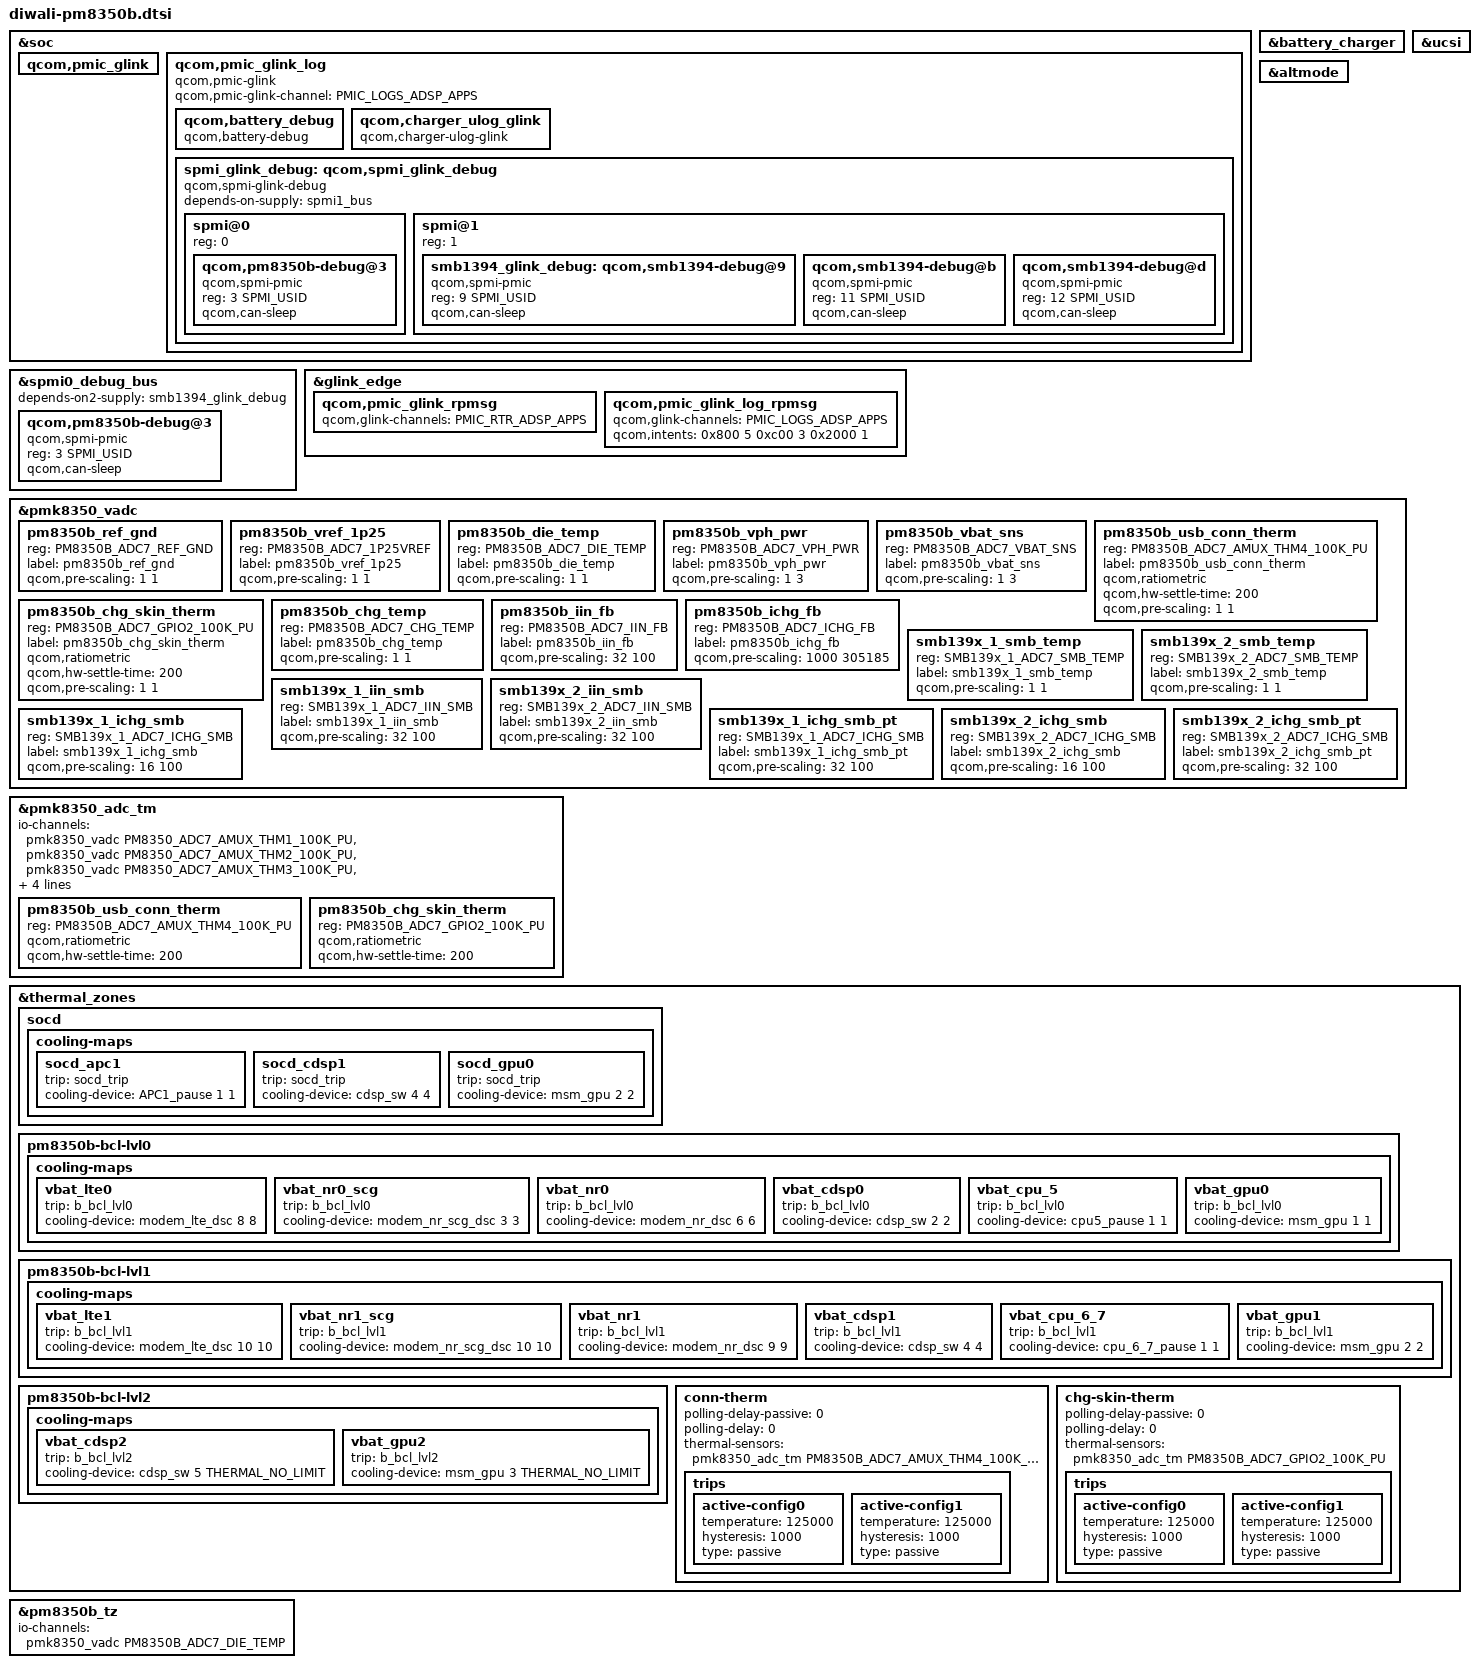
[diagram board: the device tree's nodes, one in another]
#include <dt-bindings/clock/qcom,rpmh.h>
#include <dt-bindings/thermal/thermal_qti.h>
#include <dt-bindings/iio/qcom,spmi-adc7-pm8350b.h>
#include <dt-bindings/iio/qcom,spmi-adc7-smb139x.h>
#include "pm8350b.dtsi"

&soc {
	qcom,pmic_glink {
		status = "okay";
	};

	qcom,pmic_glink_log {
		compatible = "qcom,pmic-glink";
		qcom,pmic-glink-channel = "PMIC_LOGS_ADSP_APPS";

		qcom,battery_debug {
			compatible = "qcom,battery-debug";
		};

		qcom,charger_ulog_glink {
			compatible = "qcom,charger-ulog-glink";
		};

		spmi_glink_debug: qcom,spmi_glink_debug {
			compatible = "qcom,spmi-glink-debug";
			#address-cells = <1>;
			#size-cells = <0>;
			depends-on-supply = <&spmi1_bus>;

			/* Primary SPMI bus */
			spmi@0 {
				reg = <0>;
				#address-cells = <2>;
				#size-cells = <0>;

				qcom,pm8350b-debug@3 {
					compatible = "qcom,spmi-pmic";
					reg = <3 SPMI_USID>;
					qcom,can-sleep;
				};
			};

			/* Secondary SPMI bus */
			spmi@1 {
				reg = <1>;
				#address-cells = <2>;
				#size-cells = <0>;

				smb1394_glink_debug: qcom,smb1394-debug@9 {
					compatible = "qcom,spmi-pmic";
					reg = <9 SPMI_USID>;
					qcom,can-sleep;
				};

				qcom,smb1394-debug@b {
					compatible = "qcom,spmi-pmic";
					reg = <11 SPMI_USID>;
					qcom,can-sleep;
				};

				qcom,smb1394-debug@d {
					compatible = "qcom,spmi-pmic";
					reg = <12 SPMI_USID>;
					qcom,can-sleep;
				};
			};
		};
	};
};

&spmi0_debug_bus {
	depends-on2-supply = <&smb1394_glink_debug>;
	qcom,pm8350b-debug@3 {
		compatible = "qcom,spmi-pmic";
		reg = <3 SPMI_USID>;
		#address-cells = <2>;
		#size-cells = <0>;
		qcom,can-sleep;
	};
};

&glink_edge {
	qcom,pmic_glink_rpmsg {
		qcom,glink-channels = "PMIC_RTR_ADSP_APPS";
	};

	qcom,pmic_glink_log_rpmsg {
		qcom,glink-channels = "PMIC_LOGS_ADSP_APPS";
		qcom,intents = <0x800  5
			0xc00 3
			0x2000 1>;
	};
};

&battery_charger {
	status = "okay";
};

&ucsi {
	status = "okay";
};

&altmode {
	status = "okay";
};

&pmk8350_vadc {
	pm8350b_ref_gnd {
		reg = <PM8350B_ADC7_REF_GND>;
		label = "pm8350b_ref_gnd";
		qcom,pre-scaling = <1 1>;
	};

	pm8350b_vref_1p25 {
		reg = <PM8350B_ADC7_1P25VREF>;
		label = "pm8350b_vref_1p25";
		qcom,pre-scaling = <1 1>;
	};

	pm8350b_die_temp {
		reg = <PM8350B_ADC7_DIE_TEMP>;
		label = "pm8350b_die_temp";
		qcom,pre-scaling = <1 1>;
	};

	pm8350b_vph_pwr {
		reg = <PM8350B_ADC7_VPH_PWR>;
		label = "pm8350b_vph_pwr";
		qcom,pre-scaling = <1 3>;
	};

	pm8350b_vbat_sns {
		reg = <PM8350B_ADC7_VBAT_SNS>;
		label = "pm8350b_vbat_sns";
		qcom,pre-scaling = <1 3>;
	};

	pm8350b_usb_conn_therm {
		reg = <PM8350B_ADC7_AMUX_THM4_100K_PU>;
		label = "pm8350b_usb_conn_therm";
		qcom,ratiometric;
		qcom,hw-settle-time = <200>;
		qcom,pre-scaling = <1 1>;
	};

	pm8350b_chg_skin_therm {
		reg = <PM8350B_ADC7_GPIO2_100K_PU>;
		label = "pm8350b_chg_skin_therm";
		qcom,ratiometric;
		qcom,hw-settle-time = <200>;
		qcom,pre-scaling = <1 1>;
	};

	pm8350b_chg_temp {
		reg = <PM8350B_ADC7_CHG_TEMP>;
		label = "pm8350b_chg_temp";
		qcom,pre-scaling = <1 1>;
	};

	pm8350b_iin_fb {
		reg = <PM8350B_ADC7_IIN_FB>;
		label = "pm8350b_iin_fb";
		qcom,pre-scaling = <32 100>;
	};

	pm8350b_ichg_fb {
		reg = <PM8350B_ADC7_ICHG_FB>;
		label = "pm8350b_ichg_fb";
		qcom,pre-scaling = <1000 305185>;
	};

	smb139x_1_smb_temp {
		reg = <SMB139x_1_ADC7_SMB_TEMP>;
		label = "smb139x_1_smb_temp";
		qcom,pre-scaling = <1 1>;
	};

	smb139x_2_smb_temp {
		reg = <SMB139x_2_ADC7_SMB_TEMP>;
		label = "smb139x_2_smb_temp";
		qcom,pre-scaling = <1 1>;
	};

	smb139x_1_iin_smb {
		reg = <SMB139x_1_ADC7_IIN_SMB>;
		label = "smb139x_1_iin_smb";
		qcom,pre-scaling = <32 100>;
	};

	smb139x_2_iin_smb {
		reg = <SMB139x_2_ADC7_IIN_SMB>;
		label = "smb139x_2_iin_smb";
		qcom,pre-scaling = <32 100>;
	};

	smb139x_1_ichg_smb {
		reg = <SMB139x_1_ADC7_ICHG_SMB>;
		label = "smb139x_1_ichg_smb";
		qcom,pre-scaling = <16 100>;
	};

	smb139x_1_ichg_smb_pt {
		reg = <SMB139x_1_ADC7_ICHG_SMB>;
		label = "smb139x_1_ichg_smb_pt";
		qcom,pre-scaling = <32 100>;
	};

	smb139x_2_ichg_smb {
		reg = <SMB139x_2_ADC7_ICHG_SMB>;
		label = "smb139x_2_ichg_smb";
		qcom,pre-scaling = <16 100>;
	};

	smb139x_2_ichg_smb_pt {
		reg = <SMB139x_2_ADC7_ICHG_SMB>;
		label = "smb139x_2_ichg_smb_pt";
		qcom,pre-scaling = <32 100>;
	};
};

&pmk8350_adc_tm {
	io-channels = <&pmk8350_vadc PM8350_ADC7_AMUX_THM1_100K_PU>,
			<&pmk8350_vadc PM8350_ADC7_AMUX_THM2_100K_PU>,
			<&pmk8350_vadc PM8350_ADC7_AMUX_THM3_100K_PU>,
			<&pmk8350_vadc PM8350_ADC7_AMUX_THM4_100K_PU>,
			<&pmk8350_vadc PMK8350_ADC7_AMUX_THM1_100K_PU>,
			<&pmk8350_vadc PM8350B_ADC7_AMUX_THM4_100K_PU>,
			<&pmk8350_vadc PM8350B_ADC7_GPIO2_100K_PU>;

	pm8350b_usb_conn_therm {
		reg = <PM8350B_ADC7_AMUX_THM4_100K_PU>;
		qcom,ratiometric;
		qcom,hw-settle-time = <200>;
	};

	pm8350b_chg_skin_therm {
		reg = <PM8350B_ADC7_GPIO2_100K_PU>;
		qcom,ratiometric;
		qcom,hw-settle-time = <200>;
	};
};

&thermal_zones {
	socd {
		cooling-maps {
			socd_apc1 {
				trip = <&socd_trip>;
				cooling-device = <&APC1_pause 1 1>;
			};

			socd_cdsp1 {
				trip = <&socd_trip>;
				cooling-device = <&cdsp_sw 4 4>;
			};

			socd_gpu0 {
				trip = <&socd_trip>;
				cooling-device = <&msm_gpu 2 2>;
			};
		};
	};


	pm8350b-bcl-lvl0 {
		cooling-maps {
			vbat_lte0 {
				trip = <&b_bcl_lvl0>;
				cooling-device = <&modem_lte_dsc 8 8>;
			};

			vbat_nr0_scg {
				trip = <&b_bcl_lvl0>;
				cooling-device = <&modem_nr_scg_dsc 3 3>;
			};

			vbat_nr0 {
				trip = <&b_bcl_lvl0>;
				cooling-device = <&modem_nr_dsc 6 6>;
			};

			vbat_cdsp0 {
				trip = <&b_bcl_lvl0>;
				cooling-device = <&cdsp_sw 2 2>;
			};

			vbat_cpu_5 {
				trip = <&b_bcl_lvl0>;
				cooling-device = <&cpu5_pause 1 1>;
			};

			vbat_gpu0 {
				trip = <&b_bcl_lvl0>;
				cooling-device = <&msm_gpu 1 1>;
			};
		};
	};

	pm8350b-bcl-lvl1 {
		cooling-maps {
			vbat_lte1 {
				trip = <&b_bcl_lvl1>;
				cooling-device = <&modem_lte_dsc 10 10>;
			};

			vbat_nr1_scg {
				trip = <&b_bcl_lvl1>;
				cooling-device = <&modem_nr_scg_dsc 10 10>;
			};

			vbat_nr1 {
				trip = <&b_bcl_lvl1>;
				cooling-device = <&modem_nr_dsc 9 9>;
			};

			vbat_cdsp1 {
				trip = <&b_bcl_lvl1>;
				cooling-device = <&cdsp_sw 4 4>;
			};

			vbat_cpu_6_7 {
				trip = <&b_bcl_lvl1>;
				cooling-device = <&cpu_6_7_pause 1 1>;
			};

			vbat_gpu1 {
				trip = <&b_bcl_lvl1>;
				cooling-device = <&msm_gpu 2 2>;
			};
		};
	};

	pm8350b-bcl-lvl2 {
		cooling-maps {
			vbat_cdsp2 {
				trip = <&b_bcl_lvl2>;
				cooling-device = <&cdsp_sw 5 THERMAL_NO_LIMIT>;
			};

			vbat_gpu2 {
				trip = <&b_bcl_lvl2>;
				cooling-device = <&msm_gpu 3 THERMAL_NO_LIMIT>;
			};
		};
	};

	conn-therm {
		polling-delay-passive = <0>;
		polling-delay = <0>;
		thermal-sensors =  <&pmk8350_adc_tm PM8350B_ADC7_AMUX_THM4_100K_PU>;
		trips {
			active-config0 {
				temperature = <125000>;
				hysteresis = <1000>;
				type = "passive";
			};

			active-config1 {
				temperature = <125000>;
				hysteresis = <1000>;
				type = "passive";
			};
		};
	};

	chg-skin-therm {
		polling-delay-passive = <0>;
		polling-delay = <0>;
		thermal-sensors = <&pmk8350_adc_tm PM8350B_ADC7_GPIO2_100K_PU>;
		trips {
			active-config0 {
				temperature = <125000>;
				hysteresis = <1000>;
				type = "passive";
			};

			active-config1 {
				temperature = <125000>;
				hysteresis = <1000>;
				type = "passive";
			};
		};
	};
};

&pm8350b_tz {
	io-channels = <&pmk8350_vadc PM8350B_ADC7_DIE_TEMP>;
	io-channel-names = "thermal";
};
